# EFM32TG11B120F128IM64 register map
File version: 4.2.0
CPU: CM0PLUS r0p1, little endian, MPU, no FPU, 3 interrupt priority bits
Registers are 32-bit, read-write, reset 0x0 unless marked. A register's access mark holds for its fields unless they carry their own. Offsets are from the block's base; [hi:lo] are bit positions; {n}, {i} and the like mark numbered series; 'fields as' and 'values as' point back to an identical list.

## CSEN
Base 0x4008E000
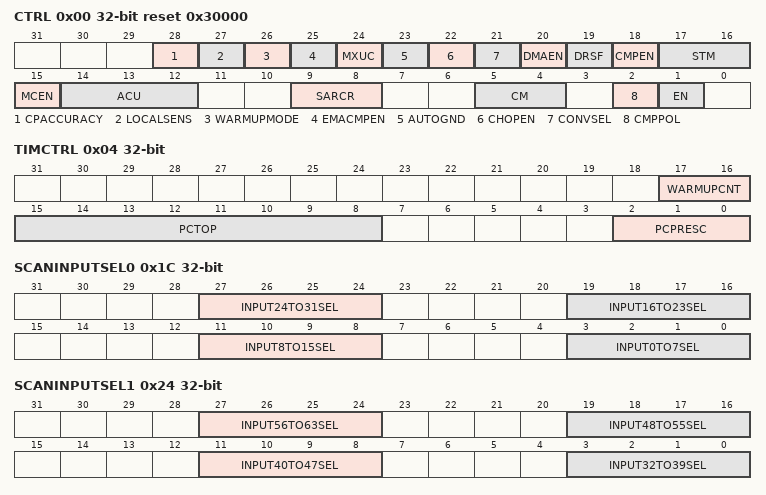
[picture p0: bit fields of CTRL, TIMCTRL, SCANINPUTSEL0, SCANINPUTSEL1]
0x00 CTRL reset 0x30000 — Control
  [28] CPACCURACY — Charge Pump Accuracy
  [27] LOCALSENS — Local Sensing Enable
  [26] WARMUPMODE — Select Warmup Mode for CSEN
  [25] EMACMPEN — Greater and Less Than Comparison Using the Exponential Moving Average (EMA) is Enabled
  [24] MXUC — CSEN Mux Disconnect
  [23] AUTOGND — CSEN Automatic Ground Enable
  [22] CHOPEN — CSEN Chop Enable
  [21] CONVSEL — CSEN Converter Select
  [20] DMAEN — CSEN DMA Enable Bit
  [19] DRSF — CSEN Disable Right-Shift
  [18] CMPEN — CSEN Digital Comparator Enable
  [17:16] STM — Start Trigger Select
    0=PRS (PRS Triggering. Conversions are triggered by the PRS channel selected in PRSSEL.); 1=TIMER (Timer Triggering. Conversions are triggered by a local CSEN timer reload.); 2=START (Software Triggering. Conversions are triggered by writing a 1 to the START field of the CMD register.)
  [15] MCEN — CSEN Multiple Channel Enable
  [14:12] ACU — CSEN Accumulator Mode Select
    0=ACC1 (Accumulate 1 sample.); 1=ACC2 (Accumulate 2 sample.); 2=ACC4 (Accumulate 4 sample.); 3=ACC8 (Accumulate 8 sample.); 4=ACC16 (Accumulate 16 sample.); 5=ACC32 (Accumulate 32 sample.); 6=ACC64 (Accumulate 64 sample.)
  [9:8] SARCR — SAR Conversion Resolution.
    0=CLK10 (Conversions last 10 internal CSEN clocks and are 10-bits in length.); 1=CLK12 (Conversions last 12 internal CSEN clocks and are 12-bits in length.); 2=CLK14 (Conversions last 14 internal CSEN clocks and are 14-bits in length.); 3=CLK16 (Conversions last 16 internal CSEN clocks and are 16-bits in length.)
  [5:4] CM — CSEN Conversion Mode Select
    0=SGL (Single Channel Mode: One conversion of a single channel (when MCE = 0) or set of bonded channels (when MCE = 1) per conversion trigger.); 1=SCAN (Scan Mode: Scans multiple selected channels once per conversion trigger.); 2=CONTSGL (Continuous Single Channel: Continuous conversion of a single channel (when MCE = 0) or set of bonded channels (when MCE = 1).); 3=CONTSCAN (Continuous Scan Mode: Continuously scans multiple selected channels.)
  [2] CMPPOL — CSEN Digital Comparator Polarity Select
  [1] EN — CSEN Enable
0x04 TIMCTRL — Timing Control
  [17:16] WARMUPCNT — Warmup Period Counter
  [15:8] PCTOP — Period Counter Top Value
  [2:0] PCPRESC — Period Counter Prescaler
    0=DIV1 (The period counter clock frequency is LFBCLKCSEN/1); 1=DIV2 (The period counter clock frequency is LFBCLKCSEN/2); 2=DIV4 (The period counter clock frequency is LFBCLKCSEN/4); 3=DIV8 (The period counter clock frequency is LFBCLKCSEN/8); 4=DIV16 (The period counter clock frequency is LFBCLKCSEN/16); 5=DIV32 (The period counter clock frequency is LFBCLKCSEN/32); 6=DIV64 (The period counter clock frequency is LFBCLKCSEN/64); 7=DIV128 (The period counter clock frequency is LFBCLKCSEN/128)
0x08 CMD wo — Command
  [0] START — Start Software-Triggered Conversions
0x0C STATUS ro
  [0] CSENBUSY — Busy Flag
0x10 PRSSEL — PRS Select
  [2:0] PRSSEL — PRS Channel Select
    {v}=PRSCH{v} (PRS Channel {v} selected as the start trigger) (v=0..7)
0x14 DATA — Output Data
0x18 SCANMASK0 — Scan Channel Mask 0
  [31:0] SCANINPUTEN — Scan Channel Mask
0x1C SCANINPUTSEL0 — Scan Input Selection 0
  [all] fields
    4=APORT1CH0TO7; 5=APORT1CH8TO15; 6=APORT1CH16TO23; 7=APORT1CH24TO31; 12=APORT3CH0TO7; 13=APORT3CH8TO15; 14=APORT3CH16TO23; 15=APORT3CH24TO31
  [27:24] INPUT24TO31SEL — CSEN_INPUT24-31 Select
  [19:16] INPUT16TO23SEL — CSEN_INPUT16-23 Select
  [11:8] INPUT8TO15SEL — CSEN_INPUT8-15 Select
  [3:0] INPUT0TO7SEL — CSEN_INPUT0-7 Select
0x20 SCANMASK1 — Scan Channel Mask 1
  [31:0] SCANINPUTEN — Scan Channel Mask.
0x24 SCANINPUTSEL1 — Scan Input Selection 1
  [all] fields
    values as the fields of SCANINPUTSEL0
  [27:24] INPUT56TO63SEL — CSEN_INPUT56-63 Select
  [19:16] INPUT48TO55SEL — CSEN_INPUT48-55 Select
  [11:8] INPUT40TO47SEL — CSEN_INPUT40-47 Select
  [3:0] INPUT32TO39SEL — CSEN_INPUT32-39 Select
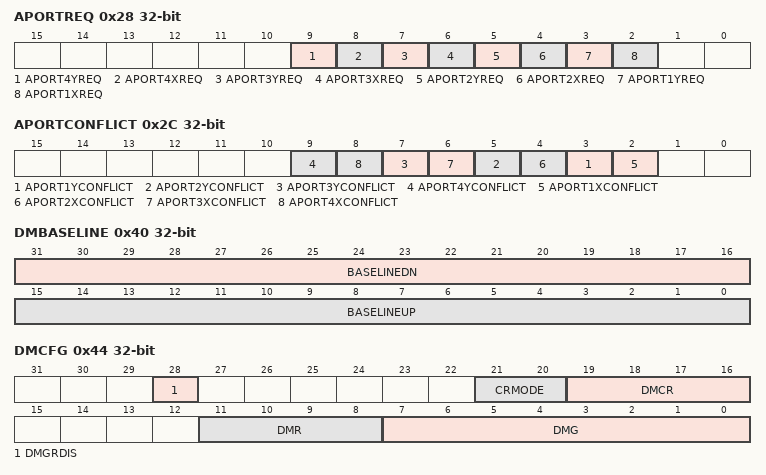
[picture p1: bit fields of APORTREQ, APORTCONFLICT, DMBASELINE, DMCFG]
0x28 APORTREQ ro — APORT Request Status
  [9] APORT4YREQ — 1 If the Bus Connected to APORT4Y is Requested
  [8] APORT4XREQ — 1 If the Bus Connected to APORT4X is Requested
  [7] APORT3YREQ — 1 If the Bus Connected to APORT3Y is Requested
  [6] APORT3XREQ — 1 If the Bus Connected to APORT3X is Requested
  [5] APORT2YREQ — 1 If the Bus Connected to APORT2Y is Requested
  [4] APORT2XREQ — 1 If the Bus Connected to APORT2X is Requested
  [3] APORT1YREQ — 1 If the Bus Connected to APORT1X is Requested
  [2] APORT1XREQ — 1 If the Bus Connected to APORT2X is Requested
0x2C APORTCONFLICT ro — APORT Request Conflict
  [2n+1] APORT{n}YCONFLICT (n=1..4) — 1 If the Bus Connected to APORT{n}Y is in Conflict With Another Peripheral
  [2n] APORT{n}XCONFLICT (n=1..4) — 1 If the Bus Connected to APORT{n}X is in Conflict With Another Peripheral
0x30 CMPTHR — Comparator Threshold
  [15:0] CMPTHR — Comparator Threshold.
0x34 EMA — Exponential Moving Average
  [21:0] EMA — Calculated Exponential Moving Average
0x38 EMACTRL — Exponential Moving Average Control
  [2:0] EMASAMPLE — EMA Sample Weight
    0=W1 (EMA weight (N) is 1.); 1=W2 (EMA weight (N) is 2.); 2=W4 (EMA weight (N) is 4.); 3=W8 (EMA weight (N) is 8.); 4=W16 (EMA weight (N) is 16.); 5=W32 (EMA weight (N) is 32.); 6=W64 (EMA weight (N) is 64.)
0x3C SINGLECTRL — Single Conversion Control
  [10:4] SINGLESEL — Single Channel Input Select
    32=APORT1XCH0; 33=APORT1YCH1; 34=APORT1XCH2; 35=APORT1YCH3; 36=APORT1XCH4; 37=APORT1YCH5; 38=APORT1XCH6; 39=APORT1YCH7; 40=APORT1XCH8; 41=APORT1YCH9; 42=APORT1XCH10; 43=APORT1YCH11; 44=APORT1XCH12; 45=APORT1YCH13; 46=APORT1XCH14; 47=APORT1YCH15; 48=APORT1XCH16; 49=APORT1YCH17; 50=APORT1XCH18; 51=APORT1YCH19; 52=APORT1XCH20; 53=APORT1YCH21; 54=APORT1XCH22; 55=APORT1YCH23; 56=APORT1XCH24; 57=APORT1YCH25; 58=APORT1XCH26; 59=APORT1YCH27; 60=APORT1XCH28; 61=APORT1YCH29; 62=APORT1XCH30; 63=APORT1YCH31; 96=APORT3XCH0; 97=APORT3YCH1; 98=APORT3XCH2; 99=APORT3YCH3; 100=APORT3XCH4; 101=APORT3YCH5; 102=APORT3XCH6; 103=APORT3YCH7; 104=APORT3XCH8; 105=APORT3YCH9; 106=APORT3XCH10; 107=APORT3YCH11; 108=APORT3XCH12; 109=APORT3YCH13; 110=APORT3XCH14; 111=APORT3YCH15; 112=APORT3XCH16; 113=APORT3YCH17; 114=APORT3XCH18; 115=APORT3YCH19; 116=APORT3XCH20; 117=APORT3YCH21; 118=APORT3XCH22; 119=APORT3YCH23; 120=APORT3XCH24; 121=APORT3YCH25; 122=APORT3XCH26; 123=APORT3YCH27; 124=APORT3XCH28; 125=APORT3YCH29; 126=APORT3XCH30; 127=APORT3YCH31
0x40 DMBASELINE — Delta Modulation Baseline
  [31:16] BASELINEDN — Delta Modulator Integrator Initial Value
  [15:0] BASELINEUP — Delta Modulator Integrator Initial Value
0x44 DMCFG — Delta Modulation Configuration
  [28] DMGRDIS — Delta Modulation Gain Step Reduction Disable
  [21:20] CRMODE — Delta Modulator Conversion Resolution.
    0=DM10 (10-bit delta modulator); 1=DM12 (12-bit delta modulator); 2=DM14 (14-bit delta modulator); 3=DM16 (16-bit delta modulator)
  [19:16] DMCR — Delta Modulator Conversion Rate
  [11:8] DMR — Delta Modulator Gain Reduction Interval
  [7:0] DMG — Delta Modulator Gain Step
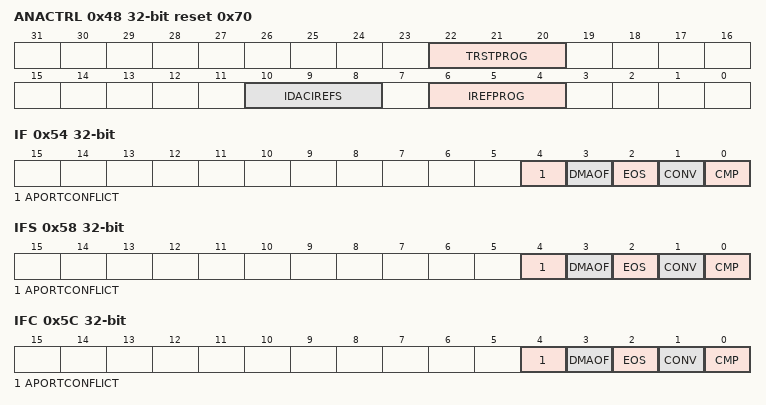
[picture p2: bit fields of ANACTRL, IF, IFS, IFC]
0x48 ANACTRL reset 0x70 — Analog Control
  [22:20] TRSTPROG — Reset Timing
  [10:8] IDACIREFS — Current DAC and Reference Current Scale
  [6:4] IREFPROG — Reference Current Control.
0x54 IF ro — Interrupt Flag
  [4] APORTCONFLICT — APORT Conflict Interrupt Flag
  [3] DMAOF — DMA Overflow Interrupt Flag.
  [2] EOS — End of Scan Interrupt Flag.
  [1] CONV — Conversion Done Interrupt Flag
  [0] CMP — Digital Comparator Interrupt Flag
0x58 IFS wo — Interrupt Flag Set
  [4] APORTCONFLICT — Set APORTCONFLICT Interrupt Flag
  [3] DMAOF — Set DMAOF Interrupt Flag
  [2] EOS — Set EOS Interrupt Flag
  [1] CONV — Set CONV Interrupt Flag
  [0] CMP — Set CMP Interrupt Flag
0x5C IFC wo — Interrupt Flag Clear
  [4] APORTCONFLICT — Clear APORTCONFLICT Interrupt Flag
  [3] DMAOF — Clear DMAOF Interrupt Flag
  [2] EOS — Clear EOS Interrupt Flag
  [1] CONV — Clear CONV Interrupt Flag
  [0] CMP — Clear CMP Interrupt Flag
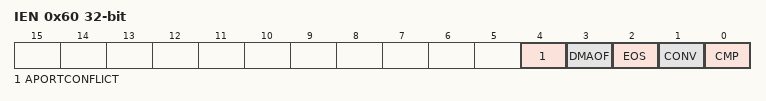
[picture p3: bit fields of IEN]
0x60 IEN — Interrupt Enable
  [4] APORTCONFLICT — APORTCONFLICT Interrupt Enable
  [3] DMAOF — DMAOF Interrupt Enable
  [2] EOS — EOS Interrupt Enable
  [1] CONV — CONV Interrupt Enable
  [0] CMP — CMP Interrupt Enable

## Notices in the file
# License
Copyright 2022 Silicon Laboratories Inc. www.silabs.com
SPDX-License-Identifier: Zlib
The licensor of this software is Silicon Laboratories Inc.
This software is provided 'as-is', without any express or implied
warranty. In no event will the authors be held liable for any damages
arising from the use of this software.
Permission is granted to anyone to use this software for any purpose,
including commercial applications, and to alter it and redistribute it
freely, subject to the following restrictions:
1. The origin of this software must not be misrepresented; you must not
claim that you wrote the original software. If you use this software
in a product, an acknowledgment in the product documentation would be
appreciated but is not required.
2. Altered source versions must be plainly marked as such, and must not be
misrepresented as being the original software.
3. This notice may not be removed or altered from any source distribution.
